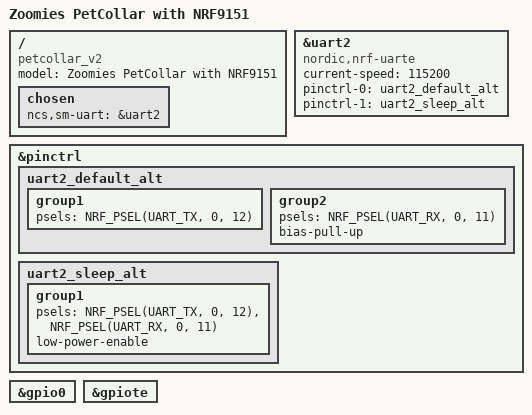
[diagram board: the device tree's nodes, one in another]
/*
 * Copyright (c) 2024 Nordic Semiconductor ASA
 *
 * SPDX-License-Identifier: LicenseRef-Nordic-5-Clause
 */

 / {
    model = "Zoomies PetCollar with NRF9151";
	compatible = "petcollar_v2";

    chosen {
        ncs,sm-uart = &uart2;
    };
};

&uart2 {
    compatible = "nordic,nrf-uarte";
    current-speed = <115200>;
    status = "okay";
    pinctrl-0 = <&uart2_default_alt>;
    pinctrl-1 = <&uart2_sleep_alt>;
    pinctrl-names = "default", "sleep";
};

&pinctrl {
    uart2_default_alt: uart2_default_alt {
        group1 {
            psels = <NRF_PSEL(UART_TX, 0, 12)>;
        };
        group2 {
            psels = <NRF_PSEL(UART_RX, 0, 11)>;
            bias-pull-up;
        };
    };

    uart2_sleep_alt: uart2_sleep_alt {
        group1 {
            psels = <NRF_PSEL(UART_TX, 0, 12)>,
                <NRF_PSEL(UART_RX, 0, 11)>;
            low-power-enable;
        };
    };
};

&gpio0 {
	status = "okay";
};

&gpiote {
	status = "okay";
};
